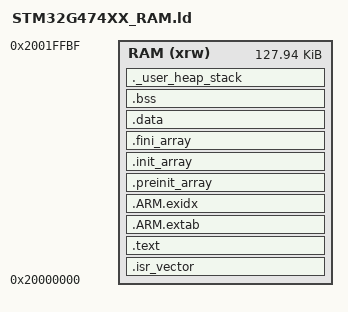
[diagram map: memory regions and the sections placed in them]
/* Transient debugger-loaded diagnostic. No section is placed in Flash. */
ENTRY(Reset_Handler)
MEMORY
{
  RAM (xrw) : ORIGIN = 0x20000000, LENGTH = 0x1FFC0
}
_estack = ORIGIN(RAM) + LENGTH(RAM);
_Min_Heap_Size = 0x200;
_Min_Stack_Size = 0x400;

SECTIONS
{
  .isr_vector :
  {
    . = ALIGN(4);
    KEEP(*(.isr_vector))
    . = ALIGN(4);
  } >RAM

  .text :
  {
    . = ALIGN(4);
    *(.text .text*)
    *(.glue_7 .glue_7t)
    *(.rodata .rodata*)
    KEEP(*(.init))
    KEEP(*(.fini))
    . = ALIGN(4);
  } >RAM

  .ARM.extab : { *(.ARM.extab* .gnu.linkonce.armextab.*) } >RAM
  .ARM.exidx :
  {
    __exidx_start = .;
    *(.ARM.exidx*)
    __exidx_end = .;
  } >RAM

  .preinit_array :
  {
    PROVIDE_HIDDEN(__preinit_array_start = .);
    KEEP(*(.preinit_array*))
    PROVIDE_HIDDEN(__preinit_array_end = .);
  } >RAM
  .init_array :
  {
    PROVIDE_HIDDEN(__init_array_start = .);
    KEEP(*(SORT(.init_array.*)))
    KEEP(*(.init_array*))
    PROVIDE_HIDDEN(__init_array_end = .);
  } >RAM
  .fini_array :
  {
    PROVIDE_HIDDEN(__fini_array_start = .);
    KEEP(*(SORT(.fini_array.*)))
    KEEP(*(.fini_array*))
    PROVIDE_HIDDEN(__fini_array_end = .);
  } >RAM

  .data :
  {
    . = ALIGN(4);
    _sdata = .;
    *(.data .data*)
    *(.RamFunc .RamFunc*)
    . = ALIGN(4);
    _edata = .;
  } >RAM
  _sidata = LOADADDR(.data);

  .bss (NOLOAD) :
  {
    . = ALIGN(4);
    _sbss = .;
    *(.bss .bss*)
    *(COMMON)
    . = ALIGN(4);
    _ebss = .;
  } >RAM

  ._user_heap_stack (NOLOAD) :
  {
    . = ALIGN(8);
    end = .;
    _end = .;
    . += _Min_Heap_Size + _Min_Stack_Size;
    . = ALIGN(8);
  } >RAM

  ASSERT(_end + _Min_Heap_Size + _Min_Stack_Size <= _estack,
         "RAM diagnostic overlaps stack")
}
